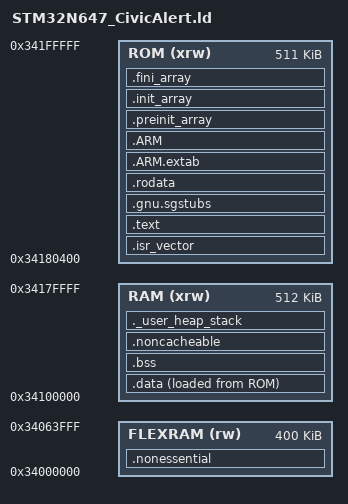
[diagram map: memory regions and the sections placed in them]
/* Entry Point */
ENTRY(Reset_Handler)

/* Highest address of the user mode stack */
_estack = ORIGIN(RAM) + LENGTH(RAM); /* end of "RAM" type memory */
_sstack = _estack - _Min_Stack_Size;

_Min_Heap_Size = 0x800 ; /* required amount of heap */
_Min_Stack_Size = 0xC350 ; /* required amount of stack */

/* Memories definition */
MEMORY
{
  ROM (xrw)    : ORIGIN = 0x34180400,   LENGTH = 511K
  RAM (xrw)    : ORIGIN = 0x34100000,   LENGTH = 512K
  FLEXRAM (rw) : ORIGIN = 0x34000000,   LENGTH = 400K
}

/* Sections */
SECTIONS
{
  /* The startup code goes into "ROM" type memory */
  .isr_vector :
  {
    . = ALIGN(4);
    KEEP(*(.isr_vector))
    . = ALIGN(4);
  } >ROM

  /* The program code and other data goes into "ROM" type memory */
  .text :
  {
    . = ALIGN(4);
    *(.text)
    *(.text*)
    *(.glue_7)         /* glue arm to thumb code */
    *(.glue_7t)        /* glue thumb to arm code */
    *(.eh_frame)
    *(.RamFunc)
    *(.RamFunc*)

    KEEP (*(.init))
    KEEP (*(.fini))

    . = ALIGN(4);
    _etext = .;        /* define a global symbols at end of code */
  } >ROM

  .gnu.sgstubs :
  {
    . = ALIGN(4);
    *(.gnu.sgstubs*)   /* Secure Gateway stubs */
    . = ALIGN(4);
  } >ROM

  /* Constant data goes into "ROM" type memory */
  .rodata :
  {
    . = ALIGN(4);
    *(.rodata)
    *(.rodata*)
    . = ALIGN(4);
  } >ROM

  .ARM.extab (READONLY) :
   {
    . = ALIGN(4);
    *(.ARM.extab* .gnu.linkonce.armextab.*)
    . = ALIGN(4);
  } >ROM

  .ARM (READONLY) :
   {
    . = ALIGN(4);
    __exidx_start = .;
    *(.ARM.exidx*)
    __exidx_end = .;
    . = ALIGN(4);
  } >ROM

  .preinit_array (READONLY) :
  {
    . = ALIGN(4);
    PROVIDE_HIDDEN (__preinit_array_start = .);
    KEEP (*(.preinit_array*))
    PROVIDE_HIDDEN (__preinit_array_end = .);
    . = ALIGN(4);
  } >ROM

  .init_array (READONLY) :
  {
    . = ALIGN(4);
    PROVIDE_HIDDEN (__init_array_start = .);
    KEEP (*(SORT(.init_array.*)))
    KEEP (*(.init_array*))
    PROVIDE_HIDDEN (__init_array_end = .);
    . = ALIGN(4);
  } >ROM

  .fini_array (READONLY) :
  {
    . = ALIGN(4);
    PROVIDE_HIDDEN (__fini_array_start = .);
    KEEP (*(SORT(.fini_array.*)))
    KEEP (*(.fini_array*))
    PROVIDE_HIDDEN (__fini_array_end = .);
    . = ALIGN(4);
  } >ROM

  /* Used by the startup to initialize data */
  _sidata = LOADADDR(.data);

  /* Initialized data sections go into "RAM" type memory */
  .data :
  {
    . = ALIGN(4);
    _sdata = .;        /* create a global symbol at data start */
    *(.data)
    *(.data*)

    . = ALIGN(4);
    _edata = .;        /* define a global symbol at data end */
  } >RAM AT> ROM

  /* Uninitialized data section goes into "RAM" type memory */
  . = ALIGN(4);
  .bss :
  {
    /* This is used by the startup in order to initialize the .bss section */
    _sbss = .;         /* define a global symbol at bss start */
    __bss_start__ = _sbss;
    *(.bss)
    *(.bss*)
    *(COMMON)

    . = ALIGN(4);
  } >RAM

  .noncacheable (NOLOAD) :
  {
    . = ALIGN(8);
    __snoncacheable = .;  /* create symbol for start of section */
    KEEP(*(.noncacheable))
    . = ALIGN(8);
    __enoncacheable = .;  /* create symbol for end of section */
    _ebss = .;            /* define a global symbol at bss end */
    __bss_end__ = _ebss;
  } >RAM

  /* User_heap_stack section, used to check that there is enough "RAM" type memory left */
  ._user_heap_stack :
  {
    . = ALIGN(8);
    PROVIDE ( end = . );
    PROVIDE ( _end = . );
    . = . + _Min_Heap_Size;
    . = . + _Min_Stack_Size;
    . = ALIGN(8);
  } >RAM
  
  /* Extra non-essential storage section */
  .nonessential (NOLOAD) :
  {
    . = ALIGN(4);
    __snonessential = .;  /* create symbol for start of section */
    KEEP(*(.nonessential))
    . = ALIGN(4);
    __enonessential = .;  /* create symbol for end of section */
  } >FLEXRAM

  /* Remove information from the compiler libraries */
  /DISCARD/ :
  {
    libc.a ( * )
    libm.a ( * )
    libgcc.a ( * )
  }

  .ARM.attributes 0 : { *(.ARM.attributes) }
}
